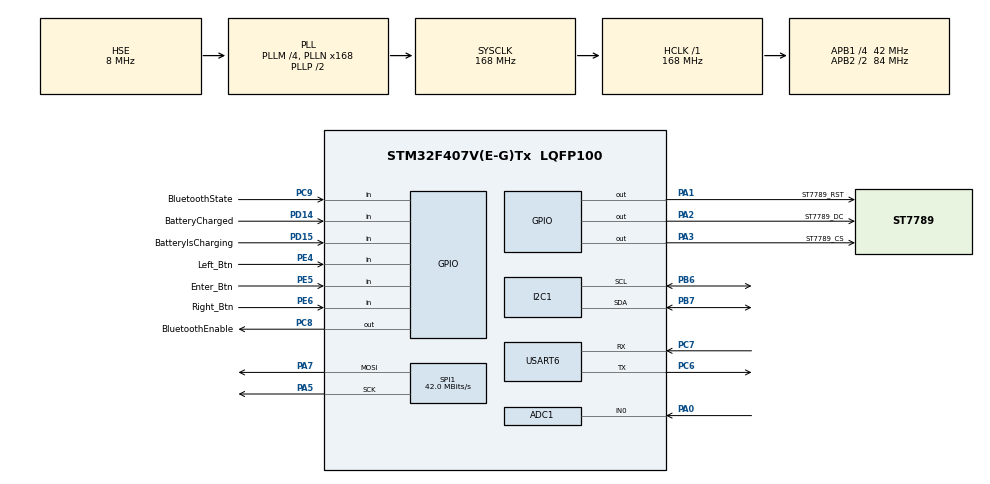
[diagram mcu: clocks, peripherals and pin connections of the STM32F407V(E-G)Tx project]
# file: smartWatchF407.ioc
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Mcu.Family=STM32F4
PH0-OSC_IN.Signal=RCC_OSC_IN
RCC.CortexFreq_Value=168000000
SPI1.VirtualType=VM_MASTER
ADC1.ContinuousConvMode=ENABLE
VP_RTC_VS_RTC_Activate.Mode=RTC_Enabled
Dma.USART6_TX.0.Mode=DMA_CIRCULAR
PE6.GPIO_Label=Right_Btn
RCC.SYSCLKSource=RCC_SYSCLKSOURCE_PLLCLK
ProjectManager.StackSize=0x400
VP_FREERTOS_VS_CMSIS_V2.Mode=CMSIS_V2
Dma.USART6_TX.0.FIFOMode=DMA_FIFOMODE_DISABLE
Dma.USART6_TX.0.Direction=DMA_MEMORY_TO_PERIPH
RTC.SynchPrediv=3124
PE5.GPIO_PuPd=GPIO_PULLUP
RCC.RCC_RTC_Clock_Source=RCC_RTCCLKSOURCE_HSE_DIV20
SPI1.Direction=SPI_DIRECTION_2LINES
Dma.USART6_TX.0.Instance=DMA2_Stream6
RCC.HCLKFreq_Value=168000000
RCC.APB2TimFreq_Value=168000000
PB6.Signal=I2C1_SCL
PC7.Signal=USART6_RX
PB6.Mode=I2C
SPI1.CalculateBaudRate=42.0 MBits/s
PE5.Signal=GPIO_Input
RCC.AHBFreq_Value=168000000
PH0-OSC_IN.Mode=HSE-External-Oscillator
ADC1.Channel-0\#ChannelRegularConversion=ADC_CHANNEL_0
RCC.HSE_VALUE=8000000
RCC.RCC_RTC_Clock_Source_FROM_HSE=RCC_RTCCLKSOURCE_HSE_DIV20
PA14.Mode=Serial_Wire
VP_SYS_VS_tim1.Mode=TIM1
TIM3.Prescaler=84
NVIC.TIM2_IRQn=true\:5\:0\:false\:false\:true\:true\:true\:true
PE4.GPIO_Label=Left_Btn
PB7.Signal=I2C1_SDA
PD14.GPIO_PuPd=GPIO_PULLUP
SH.ADCx_IN0.0=ADC1_IN0,IN0
TIM4.Period=1000
PE4.Signal=GPIO_Input
ADC1.SamplingTime-0\#ChannelRegularConversion=ADC_SAMPLETIME_480CYCLES
FREERTOS.configTOTAL_HEAP_SIZE=81920
PH1-OSC_OUT.Mode=HSE-External-Oscillator
Mcu.Package=LQFP100
TIM2.Prescaler=84
NVIC.TimeBase=TIM1_UP_TIM10_IRQn
USART6.VirtualMode=VM_ASYNC
PD15.GPIO_PuPd=GPIO_PULLUP
PA2.GPIO_Label=ST7789_DC
NVIC.TimeBaseIP=TIM1
VP_RTC_VS_RTC_Calendar.Mode=RTC_Calendar
RCC.APB2CLKDivider=RCC_HCLK_DIV2
RCC.APB1TimFreq_Value=84000000
Dma.USART6_TX.0.MemDataAlignment=DMA_MDATAALIGN_BYTE
Dma.Request0=USART6_TX
PE6.GPIO_PuPd=GPIO_PULLUP
PD15.Signal=GPIO_Input
VP_TIM3_VS_ClockSourceINT.Mode=Internal
PA3.Signal=GPIO_Output
PA5.Mode=TX_Only_Simplex_Unidirect_Master
RCC.PLLSourceVirtual=RCC_PLLSOURCE_HSE
Dma.USART6_TX.0.MemInc=DMA_MINC_ENABLE
FREERTOS.Tasks01=defaultTask,24,128,StartDefaultTask,Default,NULL,Dynamic,NULL,NULL
PD15.GPIO_Label=BatteryIsCharging
ADC1.Rank-0\#ChannelRegularConversion=1
PA7.Mode=TX_Only_Simplex_Unidirect_Master
PC9.GPIO_Label=BluetoothState
PC8.Signal=GPIO_Output
PC6.Signal=USART6_TX
RCC.APB1CLKDivider=RCC_HCLK_DIV4
PA0-WKUP.Signal=ADCx_IN0
NVIC.USART6_IRQn=true\:5\:0\:false\:false\:true\:true\:true\:true
PC8.GPIO_Label=BluetoothEnable
PA13.Signal=SYS_JTMS-SWDIO
ProjectManager.TargetToolchain=STM32CubeIDE
PC6.Mode=Asynchronous
RTC.Format=RTC_FORMAT_BIN
NVIC.DMA2_Stream6_IRQn=true\:5\:0\:false\:false\:true\:true\:false\:true
TIM4.Prescaler=84
RCC.LSE_VALUE=32768
PA1.Signal=GPIO_Output
PA5.Signal=SPI1_SCK
board=custom
RCC.VCOOutputFreq_Value=336000000
NVIC.TIM3_IRQn=true\:5\:0\:false\:false\:true\:true\:true\:true
RCC.APB2Freq_Value=84000000
VP_TIM2_VS_ClockSourceINT.Mode=Internal
SPI1.Mode=SPI_MODE_MASTER
PA1.GPIO_Label=ST7789_RST
PC9.GPIO_PuPd=GPIO_NOPULL
PH1-OSC_OUT.Signal=RCC_OSC_OUT
RCC.RCC_RTC_Clock_SourceVirtual=RCC_RTCCLKSOURCE_HSE_DIV8
Dma.USART6_TX.0.PeriphInc=DMA_PINC_DISABLE
PD14.GPIO_Label=BatteryCharged
TIM2.Period=1000
PE6.Signal=GPIO_Input
PA13.Mode=Serial_Wire
Mcu.Name=STM32F407V(E-G)Tx
PA2.Signal=GPIO_Output
PE4.GPIO_PuPd=GPIO_PULLUP
PD14.Signal=GPIO_Input
RCC.48MHZClocksFreq_Value=84000000
RCC.SYSCLKFreq_VALUE=168000000
ADC1.master=1
PE5.GPIO_Label=Enter_Btn
PB7.Mode=I2C
PA14.Signal=SYS_JTCK-SWCLK
ProjectManager.HeapSize=0x200
NVIC.TIM1_UP_TIM10_IRQn=true\:0\:0\:false\:false\:true\:false\:false\:true
RCC.HSI_VALUE=16000000
VP_TIM4_VS_ClockSourceINT.Mode=Internal
NVIC.PriorityGroup=NVIC_PRIORITYGROUP_4
ADC1.NbrOfConversionFlag=1
RCC.PLLM=4
RCC.PLLN=168
Dma.USART6_TX.0.Priority=DMA_PRIORITY_VERY_HIGH
PC9.Signal=GPIO_Input
PC7.Mode=Asynchronous
NVIC.TIM4_IRQn=true\:5\:0\:false\:false\:true\:true\:true\:true
RCC.APB1Freq_Value=42000000
Dma.USART6_TX.0.PeriphDataAlignment=DMA_PDATAALIGN_BYTE
PA3.GPIO_Label=ST7789_CS
PA7.Signal=SPI1_MOSI

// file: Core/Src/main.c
/* USER CODE BEGIN Header */
/**
  ******************************************************************************
  * @file           : main.c
  * @brief          : Main program body
  ******************************************************************************
  * @attention
  *
  * <h2><center>&copy; Copyright (c) 2021 STMicroelectronics.
  * All rights reserved.</center></h2>
  *
  * This software component is licensed by ST under BSD 3-Clause license,
  * the "License"; You may not use this file except in compliance with the
  * License. You may obtain a copy of the License at:
  *                        opensource.org/licenses/BSD-3-Clause
  *
  ******************************************************************************
  */
/* USER CODE END Header */
#include "main.h"
#include "cmsis_os.h"

/* USER CODE BEGIN Includes */
#include "tOSbaga.h"
/* USER CODE END Includes */

ADC_HandleTypeDef hadc1;

I2C_HandleTypeDef hi2c1;

RTC_HandleTypeDef hrtc;

SPI_HandleTypeDef hspi1;

TIM_HandleTypeDef htim2;
TIM_HandleTypeDef htim3;
TIM_HandleTypeDef htim4;

UART_HandleTypeDef huart6;
DMA_HandleTypeDef hdma_usart6_tx;

/* Definitions for defaultTask */
osThreadId_t defaultTaskHandle;
const osThreadAttr_t defaultTask_attributes = {
  .name = "defaultTask",
  .priority = (osPriority_t) osPriorityNormal,
  .stack_size = 128 * 4
};

void SystemClock_Config(void);
static void MX_GPIO_Init(void);
static void MX_DMA_Init(void);
static void MX_I2C1_Init(void);
static void MX_RTC_Init(void);
static void MX_SPI1_Init(void);
static void MX_TIM2_Init(void);
static void MX_TIM3_Init(void);
static void MX_TIM4_Init(void);
static void MX_USART6_UART_Init(void);
static void MX_ADC1_Init(void);
void StartDefaultTask(void *argument);

int main(void)
{

  /* MCU Configuration--------------------------------------------------------*/

  /* Reset of all peripherals, Initializes the Flash interface and the Systick. */
  HAL_Init();

  /* Configure the system clock */
  SystemClock_Config();

  /* Initialize all configured peripherals */
  MX_GPIO_Init();
  MX_DMA_Init();
  MX_I2C1_Init();
  MX_RTC_Init();
  MX_SPI1_Init();
  MX_TIM2_Init();
  MX_TIM3_Init();
  MX_TIM4_Init();
  MX_USART6_UART_Init();
  MX_ADC1_Init();
  /* USER CODE BEGIN 2 */
tos_tasks_init();

//  tos_Tft_init();
//  tos_Screen_Init();
//	ST7789_UnSelect();

 // tos_ThemeSettingsScreen_Init(1);
////	HAL_TIM_Base_Start_IT(&htim4);
  /* USER CODE END 2 */

  /* Init scheduler */
  osKernelInitialize();

  /* Create the thread(s) */
  /* creation of defaultTask */
  defaultTaskHandle = osThreadNew(StartDefaultTask, NULL, &defaultTask_attributes);

  /* Start scheduler */
  osKernelStart();

  /* We should never get here as control is now taken by the scheduler */
  /* Infinite loop */
  while (1)
  {

  }
}

void SystemClock_Config(void)
{
  RCC_OscInitTypeDef RCC_OscInitStruct = {0};
  RCC_ClkInitTypeDef RCC_ClkInitStruct = {0};
  RCC_PeriphCLKInitTypeDef PeriphClkInitStruct = {0};

  /** Configure the main internal regulator output voltage
  */
  __HAL_RCC_PWR_CLK_ENABLE();
  __HAL_PWR_VOLTAGESCALING_CONFIG(PWR_REGULATOR_VOLTAGE_SCALE1);
  /** Initializes the RCC Oscillators according to the specified parameters
  * in the RCC_OscInitTypeDef structure.
  */
  RCC_OscInitStruct.OscillatorType = RCC_OSCILLATORTYPE_HSE;
  RCC_OscInitStruct.HSEState = RCC_HSE_ON;
  RCC_OscInitStruct.PLL.PLLState = RCC_PLL_ON;
  RCC_OscInitStruct.PLL.PLLSource = RCC_PLLSOURCE_HSE;
  RCC_OscInitStruct.PLL.PLLM = 4;
  RCC_OscInitStruct.PLL.PLLN = 168;
  RCC_OscInitStruct.PLL.PLLP = RCC_PLLP_DIV2;
  RCC_OscInitStruct.PLL.PLLQ = 4;
  if (HAL_RCC_OscConfig(&RCC_OscInitStruct) != HAL_OK)
  {
    Error_Handler();
  }
  /** Initializes the CPU, AHB and APB buses clocks
  */
  RCC_ClkInitStruct.ClockType = RCC_CLOCKTYPE_HCLK|RCC_CLOCKTYPE_SYSCLK
                              |RCC_CLOCKTYPE_PCLK1|RCC_CLOCKTYPE_PCLK2;
  RCC_ClkInitStruct.SYSCLKSource = RCC_SYSCLKSOURCE_PLLCLK;
  RCC_ClkInitStruct.AHBCLKDivider = RCC_SYSCLK_DIV1;
  RCC_ClkInitStruct.APB1CLKDivider = RCC_HCLK_DIV4;
  RCC_ClkInitStruct.APB2CLKDivider = RCC_HCLK_DIV2;

  if (HAL_RCC_ClockConfig(&RCC_ClkInitStruct, FLASH_LATENCY_5) != HAL_OK)
  {
    Error_Handler();
  }
  PeriphClkInitStruct.PeriphClockSelection = RCC_PERIPHCLK_RTC;
  PeriphClkInitStruct.RTCClockSelection = RCC_RTCCLKSOURCE_HSE_DIV20;
  if (HAL_RCCEx_PeriphCLKConfig(&PeriphClkInitStruct) != HAL_OK)
  {
    Error_Handler();
  }
}

static void MX_ADC1_Init(void)
{

  ADC_ChannelConfTypeDef sConfig = {0};

  /** Configure the global features of the ADC (Clock, Resolution, Data Alignment and number of conversion)
  */
  hadc1.Instance = ADC1;
  hadc1.Init.ClockPrescaler = ADC_CLOCK_SYNC_PCLK_DIV4;
  hadc1.Init.Resolution = ADC_RESOLUTION_12B;
  hadc1.Init.ScanConvMode = DISABLE;
  hadc1.Init.ContinuousConvMode = ENABLE;
  hadc1.Init.DiscontinuousConvMode = DISABLE;
  hadc1.Init.ExternalTrigConvEdge = ADC_EXTERNALTRIGCONVEDGE_NONE;
  hadc1.Init.ExternalTrigConv = ADC_SOFTWARE_START;
  hadc1.Init.DataAlign = ADC_DATAALIGN_RIGHT;
  hadc1.Init.NbrOfConversion = 1;
  hadc1.Init.DMAContinuousRequests = DISABLE;
  hadc1.Init.EOCSelection = ADC_EOC_SINGLE_CONV;
  if (HAL_ADC_Init(&hadc1) != HAL_OK)
  {
    Error_Handler();
  }
  /** Configure for the selected ADC regular channel its corresponding rank in the sequencer and its sample time.
  */
  sConfig.Channel = ADC_CHANNEL_0;
  sConfig.Rank = 1;
  sConfig.SamplingTime = ADC_SAMPLETIME_480CYCLES;
  if (HAL_ADC_ConfigChannel(&hadc1, &sConfig) != HAL_OK)
  {
    Error_Handler();
  }

}

static void MX_I2C1_Init(void)
{

  hi2c1.Instance = I2C1;
  hi2c1.Init.ClockSpeed = 100000;
  hi2c1.Init.DutyCycle = I2C_DUTYCYCLE_2;
  hi2c1.Init.OwnAddress1 = 0;
  hi2c1.Init.AddressingMode = I2C_ADDRESSINGMODE_7BIT;
  hi2c1.Init.DualAddressMode = I2C_DUALADDRESS_DISABLE;
  hi2c1.Init.OwnAddress2 = 0;
  hi2c1.Init.GeneralCallMode = I2C_GENERALCALL_DISABLE;
  hi2c1.Init.NoStretchMode = I2C_NOSTRETCH_DISABLE;
  if (HAL_I2C_Init(&hi2c1) != HAL_OK)
  {
    Error_Handler();
  }

}

static void MX_RTC_Init(void)
{

  RTC_TimeTypeDef sTime = {0};
  RTC_DateTypeDef sDate = {0};

  /** Initialize RTC Only
  */
  hrtc.Instance = RTC;
  hrtc.Init.HourFormat = RTC_HOURFORMAT_24;
  hrtc.Init.AsynchPrediv = 127;
  hrtc.Init.SynchPrediv = 3124;
  hrtc.Init.OutPut = RTC_OUTPUT_DISABLE;
  hrtc.Init.OutPutPolarity = RTC_OUTPUT_POLARITY_HIGH;
  hrtc.Init.OutPutType = RTC_OUTPUT_TYPE_OPENDRAIN;
  if (HAL_RTC_Init(&hrtc) != HAL_OK)
  {
    Error_Handler();
  }

  /** Initialize RTC and set the Time and Date
  */
  sTime.Hours = 0;
  sTime.Minutes = 0;
  sTime.Seconds = 0;
  sTime.DayLightSaving = RTC_DAYLIGHTSAVING_NONE;
  sTime.StoreOperation = RTC_STOREOPERATION_RESET;
  if (HAL_RTC_SetTime(&hrtc, &sTime, RTC_FORMAT_BIN) != HAL_OK)
  {
    Error_Handler();
  }
  sDate.WeekDay = RTC_WEEKDAY_MONDAY;
  sDate.Month = RTC_MONTH_JANUARY;
  sDate.Date = 1;
  sDate.Year = 0;

  if (HAL_RTC_SetDate(&hrtc, &sDate, RTC_FORMAT_BIN) != HAL_OK)
  {
    Error_Handler();
  }

}

static void MX_SPI1_Init(void)
{

  /* SPI1 parameter configuration*/
  hspi1.Instance = SPI1;
  hspi1.Init.Mode = SPI_MODE_MASTER;
  hspi1.Init.Direction = SPI_DIRECTION_2LINES;
  hspi1.Init.DataSize = SPI_DATASIZE_8BIT;
  hspi1.Init.CLKPolarity = SPI_POLARITY_LOW;
  hspi1.Init.CLKPhase = SPI_PHASE_1EDGE;
  hspi1.Init.NSS = SPI_NSS_SOFT;
  hspi1.Init.BaudRatePrescaler = SPI_BAUDRATEPRESCALER_2;
  hspi1.Init.FirstBit = SPI_FIRSTBIT_MSB;
  hspi1.Init.TIMode = SPI_TIMODE_DISABLE;
  hspi1.Init.CRCCalculation = SPI_CRCCALCULATION_DISABLE;
  hspi1.Init.CRCPolynomial = 10;
  if (HAL_SPI_Init(&hspi1) != HAL_OK)
  {
    Error_Handler();
  }

}

static void MX_TIM2_Init(void)
{

  TIM_ClockConfigTypeDef sClockSourceConfig = {0};
  TIM_MasterConfigTypeDef sMasterConfig = {0};

  htim2.Instance = TIM2;
  htim2.Init.Prescaler = 84;
  htim2.Init.CounterMode = TIM_COUNTERMODE_UP;
  htim2.Init.Period = 1000;
  htim2.Init.ClockDivision = TIM_CLOCKDIVISION_DIV1;
  htim2.Init.AutoReloadPreload = TIM_AUTORELOAD_PRELOAD_DISABLE;
  if (HAL_TIM_Base_Init(&htim2) != HAL_OK)
  {
    Error_Handler();
  }
  sClockSourceConfig.ClockSource = TIM_CLOCKSOURCE_INTERNAL;
  if (HAL_TIM_ConfigClockSource(&htim2, &sClockSourceConfig) != HAL_OK)
  {
    Error_Handler();
  }
  sMasterConfig.MasterOutputTrigger = TIM_TRGO_RESET;
  sMasterConfig.MasterSlaveMode = TIM_MASTERSLAVEMODE_DISABLE;
  if (HAL_TIMEx_MasterConfigSynchronization(&htim2, &sMasterConfig) != HAL_OK)
  {
    Error_Handler();
  }

}

static void MX_TIM3_Init(void)
{

  TIM_ClockConfigTypeDef sClockSourceConfig = {0};
  TIM_MasterConfigTypeDef sMasterConfig = {0};

  htim3.Instance = TIM3;
  htim3.Init.Prescaler = 84;
  htim3.Init.CounterMode = TIM_COUNTERMODE_UP;
  htim3.Init.Period = 65535;
  htim3.Init.ClockDivision = TIM_CLOCKDIVISION_DIV1;
  htim3.Init.AutoReloadPreload = TIM_AUTORELOAD_PRELOAD_DISABLE;
  if (HAL_TIM_Base_Init(&htim3) != HAL_OK)
  {
    Error_Handler();
  }
  sClockSourceConfig.ClockSource = TIM_CLOCKSOURCE_INTERNAL;
  if (HAL_TIM_ConfigClockSource(&htim3, &sClockSourceConfig) != HAL_OK)
  {
    Error_Handler();
  }
  sMasterConfig.MasterOutputTrigger = TIM_TRGO_RESET;
  sMasterConfig.MasterSlaveMode = TIM_MASTERSLAVEMODE_DISABLE;
  if (HAL_TIMEx_MasterConfigSynchronization(&htim3, &sMasterConfig) != HAL_OK)
  {
    Error_Handler();
  }

}

static void MX_TIM4_Init(void)
{

  TIM_ClockConfigTypeDef sClockSourceConfig = {0};
  TIM_MasterConfigTypeDef sMasterConfig = {0};

  htim4.Instance = TIM4;
  htim4.Init.Prescaler = 84;
  htim4.Init.CounterMode = TIM_COUNTERMODE_UP;
  htim4.Init.Period = 1000;
  htim4.Init.ClockDivision = TIM_CLOCKDIVISION_DIV1;
  htim4.Init.AutoReloadPreload = TIM_AUTORELOAD_PRELOAD_DISABLE;
  if (HAL_TIM_Base_Init(&htim4) != HAL_OK)
  {
    Error_Handler();
  }
  sClockSourceConfig.ClockSource = TIM_CLOCKSOURCE_INTERNAL;
  if (HAL_TIM_ConfigClockSource(&htim4, &sClockSourceConfig) != HAL_OK)
  {
    Error_Handler();
  }
  sMasterConfig.MasterOutputTrigger = TIM_TRGO_RESET;
  sMasterConfig.MasterSlaveMode = TIM_MASTERSLAVEMODE_DISABLE;
  if (HAL_TIMEx_MasterConfigSynchronization(&htim4, &sMasterConfig) != HAL_OK)
  {
    Error_Handler();
  }

}

static void MX_USART6_UART_Init(void)
{

  huart6.Instance = USART6;
  huart6.Init.BaudRate = 115200;
  huart6.Init.WordLength = UART_WORDLENGTH_8B;
  huart6.Init.StopBits = UART_STOPBITS_1;
  huart6.Init.Parity = UART_PARITY_NONE;
  huart6.Init.Mode = UART_MODE_TX_RX;
  huart6.Init.HwFlowCtl = UART_HWCONTROL_NONE;
  huart6.Init.OverSampling = UART_OVERSAMPLING_16;
  if (HAL_UART_Init(&huart6) != HAL_OK)
  {
    Error_Handler();
  }

}

static void MX_DMA_Init(void)
{

  /* DMA controller clock enable */
  __HAL_RCC_DMA2_CLK_ENABLE();

  /* DMA interrupt init */
  /* DMA2_Stream6_IRQn interrupt configuration */
  HAL_NVIC_SetPriority(DMA2_Stream6_IRQn, 5, 0);
  HAL_NVIC_EnableIRQ(DMA2_Stream6_IRQn);

}

static void MX_GPIO_Init(void)
{
  GPIO_InitTypeDef GPIO_InitStruct = {0};

  /* GPIO Ports Clock Enable */
  __HAL_RCC_GPIOE_CLK_ENABLE();
  __HAL_RCC_GPIOH_CLK_ENABLE();
  __HAL_RCC_GPIOA_CLK_ENABLE();
  __HAL_RCC_GPIOD_CLK_ENABLE();
  __HAL_RCC_GPIOC_CLK_ENABLE();
  __HAL_RCC_GPIOB_CLK_ENABLE();

  /*Configure GPIO pin Output Level */
  HAL_GPIO_WritePin(GPIOA, ST7789_RST_Pin|ST7789_DC_Pin|ST7789_CS_Pin, GPIO_PIN_RESET);

  /*Configure GPIO pin Output Level */
  HAL_GPIO_WritePin(BluetoothEnable_GPIO_Port, BluetoothEnable_Pin, GPIO_PIN_RESET);

  /*Configure GPIO pins : Left_Btn_Pin Enter_Btn_Pin Right_Btn_Pin */
  GPIO_InitStruct.Pin = Left_Btn_Pin|Enter_Btn_Pin|Right_Btn_Pin;
  GPIO_InitStruct.Mode = GPIO_MODE_INPUT;
  GPIO_InitStruct.Pull = GPIO_PULLUP;
  HAL_GPIO_Init(GPIOE, &GPIO_InitStruct);

  /*Configure GPIO pins : ST7789_RST_Pin ST7789_DC_Pin ST7789_CS_Pin */
  GPIO_InitStruct.Pin = ST7789_RST_Pin|ST7789_DC_Pin|ST7789_CS_Pin;
  GPIO_InitStruct.Mode = GPIO_MODE_OUTPUT_PP;
  GPIO_InitStruct.Pull = GPIO_NOPULL;
  GPIO_InitStruct.Speed = GPIO_SPEED_FREQ_LOW;
  HAL_GPIO_Init(GPIOA, &GPIO_InitStruct);

  /*Configure GPIO pins : BatteryCharged_Pin BatteryIsCharging_Pin */
  GPIO_InitStruct.Pin = BatteryCharged_Pin|BatteryIsCharging_Pin;
  GPIO_InitStruct.Mode = GPIO_MODE_INPUT;
  GPIO_InitStruct.Pull = GPIO_PULLUP;
  HAL_GPIO_Init(GPIOD, &GPIO_InitStruct);

  /*Configure GPIO pin : BluetoothEnable_Pin */
  GPIO_InitStruct.Pin = BluetoothEnable_Pin;
  GPIO_InitStruct.Mode = GPIO_MODE_OUTPUT_PP;
  GPIO_InitStruct.Pull = GPIO_NOPULL;
  GPIO_InitStruct.Speed = GPIO_SPEED_FREQ_LOW;
  HAL_GPIO_Init(BluetoothEnable_GPIO_Port, &GPIO_InitStruct);

  /*Configure GPIO pin : BluetoothState_Pin */
  GPIO_InitStruct.Pin = BluetoothState_Pin;
  GPIO_InitStruct.Mode = GPIO_MODE_INPUT;
  GPIO_InitStruct.Pull = GPIO_NOPULL;
  HAL_GPIO_Init(BluetoothState_GPIO_Port, &GPIO_InitStruct);

}

void StartDefaultTask(void *argument)
{
  for(;;)
  {
    osDelay(1);
  }
}

 /**
  * @brief  Period elapsed callback in non blocking mode
  * @note   This function is called  when TIM1 interrupt took place, inside
  * HAL_TIM_IRQHandler(). It makes a direct call to HAL_IncTick() to increment
  * a global variable "uwTick" used as application time base.
  * @param  htim : TIM handle
  * @retval None
  */
void HAL_TIM_PeriodElapsedCallback(TIM_HandleTypeDef *htim)
{
  if (htim->Instance == TIM1) {
    HAL_IncTick();
  }
}

void Error_Handler(void)
{
  __disable_irq();
  while (1)
  {
  }
}

/************************ (C) COPYRIGHT STMicroelectronics *****END OF FILE****/
